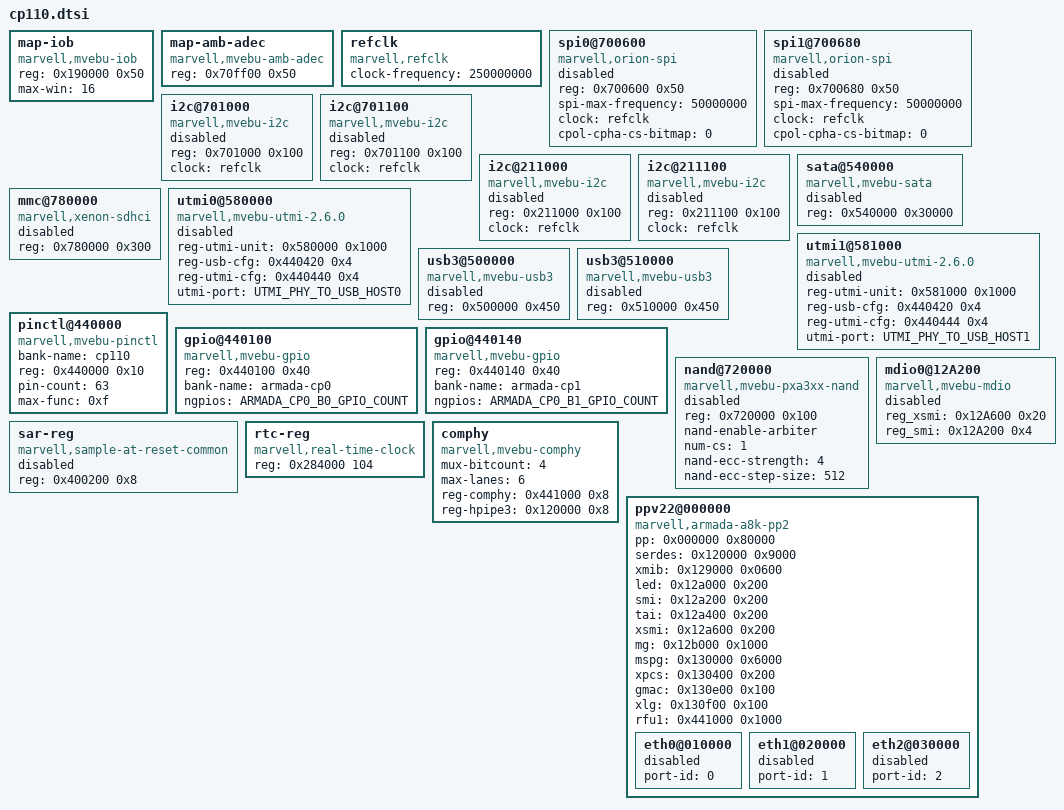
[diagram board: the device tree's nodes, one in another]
/*
 * ***************************************************************************
 * Copyright (C) 2015 Marvell International Ltd.
 * ***************************************************************************
 * This program is free software: you can redistribute it and/or modify it
 * under the terms of the GNU General Public License as published by the Free
 * Software Foundation, either version 2 of the License, or any later version.
 *
 * This program is distributed in the hope that it will be useful,
 * but WITHOUT ANY WARRANTY; without even the implied warranty of
 * MERCHANTABILITY or FITNESS FOR A PARTICULAR PURPOSE.  See the
 * GNU General Public License for more details.
 *
 * You should have received a copy of the GNU General Public License
 * along with this program.  If not, see <http://www.gnu.org/licenses/>.
 * ***************************************************************************
 */

map-iob {
	compatible = "marvell,mvebu-iob";
	reg = <0x190000 0x50>;
	max-win = <16>;
};
map-amb-adec {
	compatible = "marvell,mvebu-amb-adec";
	reg = <0x70ff00 0x50>;
};

refclk {
	compatible = "marvell,refclk";
	#clock-cells = <0>;
	clock-frequency = <250000000>;
};

spi0@700600 {
	compatible = "marvell,orion-spi";
	reg = <0x700600 0x50>;
	spi-max-frequency = <50000000>;
	clock = <&refclk>;
	cpol-cpha-cs-bitmap = <0>; /* bit i is set if the CPOL and CPHA
				      of CS-i is enabled or not */
	status = "disabled";
};

spi1@700680 {
	compatible = "marvell,orion-spi";
	reg = <0x700680 0x50>;
	spi-max-frequency = <50000000>;
	clock = <&refclk>;
	cpol-cpha-cs-bitmap = <0>; /* bit i is set if the CPOL and CPHA
				      of CS-i is enabled or not */
	status = "disabled";
};
i2c@701000 { /* i2c0 */
	compatible = "marvell,mvebu-i2c";
	reg = <0x701000 0x100>;
	clock = <&refclk>;
	status = "disabled";
};
i2c@701100 { /* i2c1 */
	compatible = "marvell,mvebu-i2c";
	reg = <0x701100 0x100>;
	clock = <&refclk>;
	status = "disabled";
};
i2c@211000 { /* MSS_i2c0 */
	compatible = "marvell,mvebu-i2c";
	reg = <0x211000 0x100>;
	clock = <&refclk>;
	status = "disabled";
};
i2c@211100 { /* MSS_i2c1 */
	compatible = "marvell,mvebu-i2c";
	reg = <0x211100 0x100>;
	clock = <&refclk>;
	status = "disabled";
};
sata@540000 {
	compatible = "marvell,mvebu-sata";
	reg = <0x540000 0x30000>;
	status = "disabled";
};
mmc@780000 {
	compatible = "marvell,xenon-sdhci";
	reg = <0x780000 0x300>;
	status = "disabled";
};
utmi0@580000 {
	compatible = "marvell,mvebu-utmi-2.6.0";
	reg-utmi-unit = <0x580000 0x1000>;
	reg-usb-cfg = <0x440420 0x4>;
	reg-utmi-cfg = <0x440440 0x4>;
	utmi-port = <UTMI_PHY_TO_USB_HOST0>;
	status = "disabled";
};
utmi1@581000 {
	compatible = "marvell,mvebu-utmi-2.6.0";
	reg-utmi-unit = <0x581000 0x1000>;
	reg-usb-cfg = <0x440420 0x4>;
	reg-utmi-cfg = <0x440444 0x4>;
	utmi-port = <UTMI_PHY_TO_USB_HOST1>;
	status = "disabled";
};
usb3@500000 { /* USB3_H0 */
	compatible = "marvell,mvebu-usb3";
	reg = <0x500000 0x450>;
	status = "disabled";
};
usb3@510000 { /* USB3_H1 */
	compatible = "marvell,mvebu-usb3";
	reg = <0x510000 0x450>;
	status = "disabled";
};

pinctl@440000 {
	compatible = "marvell,mvebu-pinctl";
	bank-name ="cp110";
	reg = <0x440000 0x10>;
	pin-count = <63>;
	max-func = <0xf>;
};

gpio@440100 {
	compatible = "marvell,mvebu-gpio";
	reg = <0x440100 0x40>;
	bank-name = "armada-cp0";
	ngpios = <ARMADA_CP0_B0_GPIO_COUNT>;
	status = "okay";
};

gpio@440140 {
	compatible = "marvell,mvebu-gpio";
	reg = <0x440140 0x40>;
	bank-name = "armada-cp1";
	ngpios = <ARMADA_CP0_B1_GPIO_COUNT>;
	status = "okay";
};

nand@720000 {
	compatible = "marvell,mvebu-pxa3xx-nand";
	reg = <0x720000 0x100>;
	#address-cells = <1>;

	nand-enable-arbiter;
	num-cs = <1>;
	nand-ecc-strength = <4>;
	nand-ecc-step-size = <512>;
	status = "disabled";
};

mdio0@12A200 {
	compatible = "marvell,mvebu-mdio";
	reg_xsmi = <0x12A600 0x20>;
	reg_smi = <0x12A200 0x4>;
	status = "disabled";
};

sar-reg {
	compatible = "marvell,sample-at-reset-common", "marvell,sample-at-reset-cp110";
	reg = <0x400200 0x8>;
	status = "disabled";
};

rtc-reg {
	compatible = "marvell,real-time-clock";
	reg = <0x284000 104>;
};

comphy {
	compatible = "marvell,mvebu-comphy", "marvell,comphy-cp110";
	mux-bitcount = <4>;
	max-lanes = <6>;
	reg-comphy = <0x441000 0x8>;
	reg-hpipe3 = <0x120000 0x8>;
};

ppv22@000000 {
	compatible = "marvell,armada-a8k-pp2";
	pp     = <0x000000 0x80000>; /* Packet Processor regs */
	serdes = <0x120000 0x9000>; /* SERDES regs */
	xmib   = <0x129000 0x0600>; /* XMIB regs */
	led    = <0x12a000 0x200>;  /* LED regs */
	smi    = <0x12a200 0x200>;  /* SMI regs */
	tai    = <0x12a400 0x200>;  /* TAI regs */
	xsmi   = <0x12a600 0x200>;  /* XSMI regs */
	mg     = <0x12b000 0x1000>;  /* MG Internal regs */
	mspg   = <0x130000 0x6000>; /* MSPG regs */
	xpcs   = <0x130400 0x200>;  /* MSPG - XPCS regs */
	gmac   = <0x130e00 0x100>;  /* MSPG - GMAC regs */
	xlg    = <0x130f00 0x100>;  /* MSPG - XLG MAC regs */
	rfu1   = <0x441000 0x1000>;  /* RFU-1 Regs */
	status = "okay";

	eth0@010000 {
		port-id = <0>; /* pp2_port_id */
		status = "disabled";
	};
	eth1@020000 {
		port-id = <1>; /* pp2_port_id */
		status = "disabled";
	};
	eth2@030000 {
		port-id = <2>; /* pp2_port_id */
		status = "disabled";
	};

};
